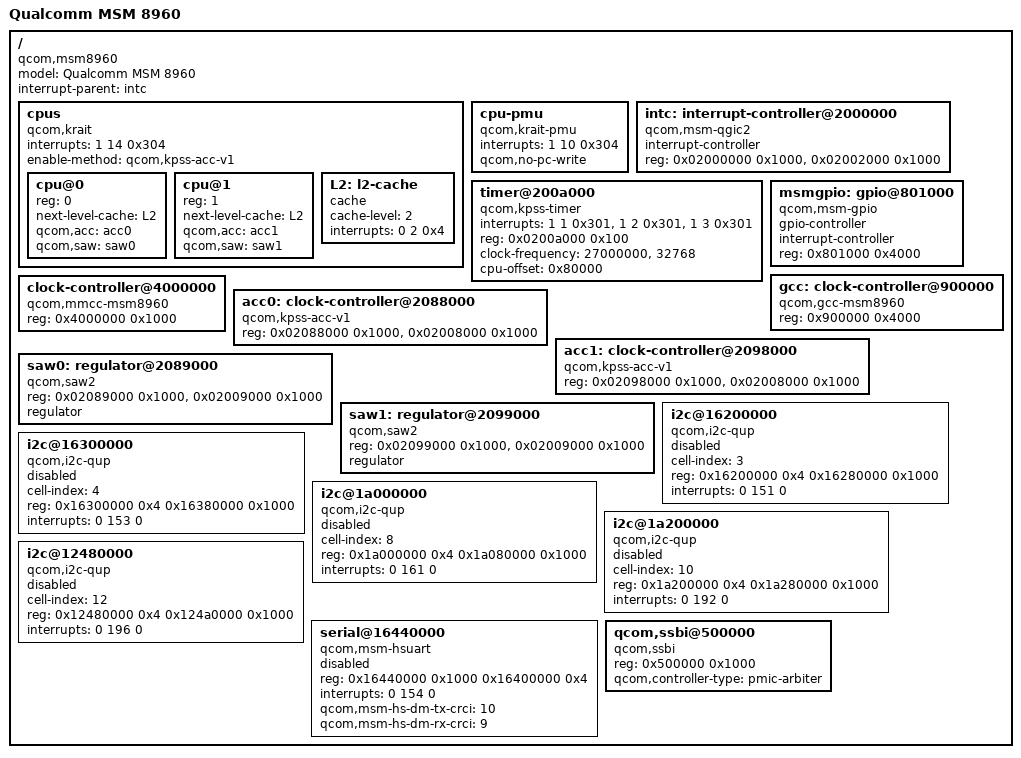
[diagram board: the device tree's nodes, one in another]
/* Copyright (c) 2012, Motorola Mobility LLC. All rights reserved.
 *
 * This program is free software; you can redistribute it and/or modify
 * it under the terms of the GNU General Public License version 2 and
 * only version 2 as published by the Free Software Foundation.
 *
 * This program is distributed in the hope that it will be useful,
 * but WITHOUT ANY WARRANTY; without even the implied warranty of
 * MERCHANTABILITY or FITNESS FOR A PARTICULAR PURPOSE.  See the
 * GNU General Public License for more details.
 */

/include/ "msm8960-pinmux.dtsi"
/include/ "msm8960-rpm-regulators.dtsi"
/include/ "msm-pm8921.dtsi"

/ {
	model = "Qualcomm MSM 8960";
	compatible = "qcom,msm8960";
	interrupt-parent = <&intc>;

	cpus {
		#address-cells = <1>;
		#size-cells = <0>;
		interrupts = <1 14 0x304>;
		compatible = "qcom,krait";
		enable-method = "qcom,kpss-acc-v1";

		cpu@0 {
			device_type = "cpu";
			reg = <0>;
			next-level-cache = <&L2>;
			qcom,acc = <&acc0>;
			qcom,saw = <&saw0>;
		};

		cpu@1 {
			device_type = "cpu";
			reg = <1>;
			next-level-cache = <&L2>;
			qcom,acc = <&acc1>;
			qcom,saw = <&saw1>;
		};

		L2: l2-cache {
			compatible = "cache";
			cache-level = <2>;
			interrupts = <0 2 0x4>;
		};
	};

	cpu-pmu {
		compatible = "qcom,krait-pmu";
		interrupts = <1 10 0x304>;
		qcom,no-pc-write;
	};

	intc: interrupt-controller@2000000 {
		compatible = "qcom,msm-qgic2";
		interrupt-controller;
		#interrupt-cells = <3>;
		reg = <0x02000000 0x1000>,
		      <0x02002000 0x1000>;
	};

	timer@200a000 {
		compatible = "qcom,kpss-timer", "qcom,msm-timer";
		interrupts = <1 1 0x301>,
			     <1 2 0x301>,
			     <1 3 0x301>;
		reg = <0x0200a000 0x100>;
		clock-frequency = <27000000>,
				  <32768>;
		cpu-offset = <0x80000>;
	}

	msmgpio: gpio@801000 {
		compatible = "qcom,msm-gpio";
		gpio-controller;
		#gpio-cells = <2>;
		interrupt-controller;
		#interrupt-cells = <2>;
		reg = <0x801000 0x4000>;
	};

	gcc: clock-controller@900000 {
		compatible = "qcom,gcc-msm8960";
		#clock-cells = <1>;
		#reset-cells = <1>;
		reg = <0x900000 0x4000>;
	};

	clock-controller@4000000 {
		compatible = "qcom,mmcc-msm8960";
		reg = <0x4000000 0x1000>;
		#clock-cells = <1>;
		#reset-cells = <1>;
	};

	acc0: clock-controller@2088000 {
		compatible = "qcom,kpss-acc-v1";
		reg = <0x02088000 0x1000>, <0x02008000 0x1000>;
	};

	acc1: clock-controller@2098000 {
		compatible = "qcom,kpss-acc-v1";
		reg = <0x02098000 0x1000>, <0x02008000 0x1000>;
	};

	saw0: regulator@2089000 {
		compatible = "qcom,saw2";
		reg = <0x02089000 0x1000>, <0x02009000 0x1000>;
		regulator;
	};

	saw1: regulator@2099000 {
		compatible = "qcom,saw2";
		reg = <0x02099000 0x1000>, <0x02009000 0x1000>;
		regulator;
	};

	/* GSBI 3 - I2C Port */
	i2c@16200000 {
		compatible = "qcom,i2c-qup";
		status = "disabled";

		#address-cells = <1>;
		#size-cells = <0>;
		cell-index = <3>;

		/*
		 * MSM_GSBI3_PHYS           0x16200000
		 * MSM_GSBI3_QUP_PHYS       (MSM_GSBI3_PHYS + 0x80000)
		 */
		reg = <0x16200000 0x4 0x16280000 0x1000>;
		reg-names = "gsbi_qup_i2c_addr", "qup_phys_addr";

		/* GSBI3_QUP_IRQ (GIC_SPI_START + 151) */
		interrupts = <0 151 0>;
		interrupt-names = "qup_err_intr";
	};

	/* GSBI 4 - I2C Port */
	i2c@16300000 {
		compatible = "qcom,i2c-qup";
		status = "disabled";

		#address-cells = <1>;
		#size-cells = <0>;
		cell-index = <4>;

		/*
		 * MSM_GSBI4_PHYS           0x16300000
		 * MSM_GSBI4_QUP_PHYS       (MSM_GSBI4_PHYS + 0x80000)
		 */
		reg = <0x16300000 0x4 0x16380000 0x1000>;
		reg-names = "gsbi_qup_i2c_addr", "qup_phys_addr";

		/* GSBI4_QUP_IRQ (GIC_SPI_START + 153) */
		interrupts = <0 153 0>;
		interrupt-names = "qup_err_intr";
	};

	/* GSBI 8 - I2C Port */
	i2c@1a000000 {
		compatible = "qcom,i2c-qup";
		status = "disabled";

		#address-cells = <1>;
		#size-cells = <0>;
		cell-index = <8>;

		/*
		 * MSM_GSBI8_PHYS           0x1A000000
		 * MSM_GSBI8_QUP_PHYS       (MSM_GSBI8_PHYS + 0x80000)
		 */
		reg = <0x1a000000 0x4 0x1a080000 0x1000>;
		reg-names = "gsbi_qup_i2c_addr", "qup_phys_addr";

		/* GSBI8_QUP_IRQ (GIC_SPI_START + 161) */
		interrupts = <0 161 0>;
		interrupt-names = "qup_err_intr";
	};

	/* GSBI 10 - I2C Port */
	i2c@1a200000 {
		compatible = "qcom,i2c-qup";
		status = "disabled";

		#address-cells = <1>;
		#size-cells = <0>;
		cell-index = <10>;

		/*
		 * MSM_GSBI10_PHYS           0x1A200000
		 * MSM_GSBI10_QUP_PHYS       (MSM_GSBI10_PHYS + 0x80000)
		 */
		reg = <0x1a200000 0x4 0x1a280000 0x1000>;
		reg-names = "gsbi_qup_i2c_addr", "qup_phys_addr";

		/* GSBI10_QUP_IRQ (GIC_SPI_START + 192) */
		interrupts = <0 192 0>;
		interrupt-names = "qup_err_intr";
	};

	/* GSBI 12 - I2C Port */
	i2c@12480000 {
		compatible = "qcom,i2c-qup";
		status = "disabled";

		#address-cells = <1>;
		#size-cells = <0>;
		cell-index = <12>;

		/*
		 * MSM_GSBI12_PHYS           0x12480000
		 * MSM_GSBI12_QUP_PHYS       (MSM_GSBI12_PHYS + 0x20000)
		 */
		reg = <0x12480000 0x4 0x124a0000 0x1000>;
		reg-names = "gsbi_qup_i2c_addr", "qup_phys_addr";

		/* GSBI12_QUP_IRQ (GIC_SPI_START + 196) */
		interrupts = <0 196 0>;
		interrupt-names = "qup_err_intr";
	};

	/* GSBI 5 - UART DM Port */
	serial@16440000 {
		compatible = "qcom,msm-hsuart";
		status = "disabled";

		/*
		 * MSM_GSBI5_PHYS          0x16400000
		 * MSM_UART5DM_PHYS        (MSM_GSBI5_PHYS + 0x40000)
		 */
		reg = <0x16440000 0x1000 0x16400000 0x4>;
		reg-names = "uartdm_resouce", "gsbi_resource";

		/* GSBI5_UARTDM_IRQ (GIC_SPI_START + 154) */
		interrupts = <0 154 0>;

		/*
		 * DMOV_HSUART_GSBI5_TX_CRCI  10
		 * DMOV_HSUART_GSBI5_RX_CRCI  9
		 */
		qcom,msm-hs-dm-tx-crci = <10>;
		qcom,msm-hs-dm-rx-crci = <9>;
	};

	qcom,ssbi@500000 {
		compatible = "qcom,ssbi";
		reg = <0x500000 0x1000>;
		qcom,controller-type = "pmic-arbiter";
	};
};
